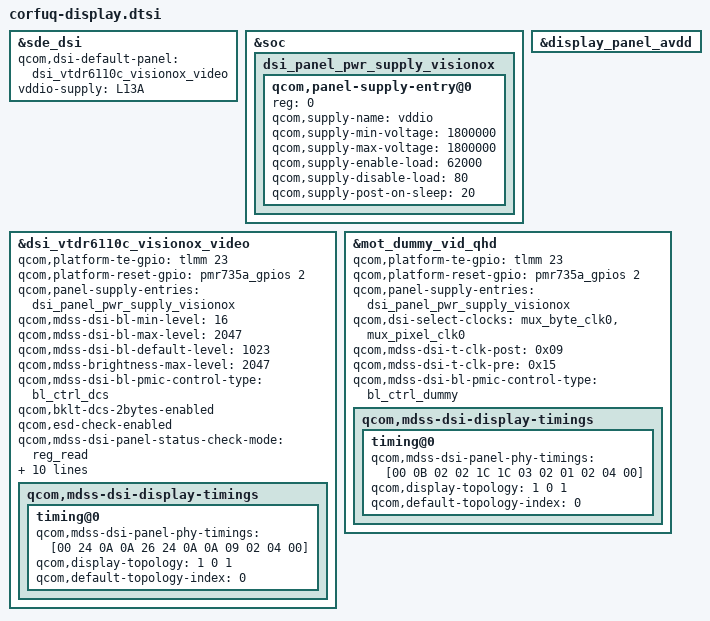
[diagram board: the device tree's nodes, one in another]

#include "dsi-panel-mot-visionox-vtdr6110c-fhd-video.dtsi"
#include "dsi-panel-mot-dummy-qhd-video.dtsi"


&sde_dsi {
	/delete-property/ qcom,dsi-default-panel;
	qcom,dsi-default-panel = <&dsi_vtdr6110c_visionox_video>;

	/delete-property/ avdd-supply;
	vddio-supply = <&L13A>;
};

&soc {
	dsi_panel_pwr_supply_visionox: dsi_panel_pwr_supply_visionox {
		#address-cells = <1>;
		#size-cells = <0>;

		qcom,panel-supply-entry@0 {
			reg = <0>;
			qcom,supply-name = "vddio";
			qcom,supply-min-voltage = <1800000>;
			qcom,supply-max-voltage = <1800000>;
			qcom,supply-enable-load = <62000>;
			qcom,supply-disable-load = <80>;
			qcom,supply-post-on-sleep = <20>;
		};
	};
};

&display_panel_avdd {
	/delete-property/ gpio;
	/delete-property/ pinctrl-0;
};

&dsi_vtdr6110c_visionox_video {
	qcom,platform-te-gpio = <&tlmm 23 0>;
	qcom,platform-reset-gpio = <&pmr735a_gpios 2 0>;

	qcom,panel-supply-entries = <&dsi_panel_pwr_supply_visionox>;

	qcom,mdss-dsi-bl-min-level = <16>;
	qcom,mdss-dsi-bl-max-level = <2047>;
	qcom,mdss-dsi-bl-default-level = <1023>;
	qcom,mdss-brightness-max-level = <2047>;
	qcom,mdss-dsi-bl-pmic-control-type = "bl_ctrl_dcs";
	qcom,bklt-dcs-2bytes-enabled;

	qcom,esd-check-enabled;
	qcom,mdss-dsi-panel-status-check-mode = "reg_read";
	qcom,mdss-dsi-panel-status-command = [06 01 00 01 00 00 01 0a];
	qcom,mdss-dsi-panel-status-command-state = "dsi_hs_mode";
	qcom,mdss-dsi-panel-status-value = <0x9c>;
	qcom,mdss-dsi-panel-status-read-length = <1>;

	qcom,dsi-select-clocks = "mux_byte_clk0", "mux_pixel_clk0";
	qcom,mdss-dsi-t-clk-post = <0x0F>;
	qcom,mdss-dsi-t-clk-pre = <0x3B>;
	qcom,mdss-dsi-display-timings {
		timing@0 {
			qcom,mdss-dsi-panel-phy-timings = [00 24 0A 0A 26 24 0A
				0A 09 02 04 00];
			qcom,display-topology = <1 0 1>;
			qcom,default-topology-index = <0>;
		};
	};
};

&mot_dummy_vid_qhd {
	qcom,platform-te-gpio = <&tlmm 23 0>;
	qcom,platform-reset-gpio = <&pmr735a_gpios 2 0>;

	qcom,panel-supply-entries = <&dsi_panel_pwr_supply_visionox>;

	qcom,dsi-select-clocks = "mux_byte_clk0", "mux_pixel_clk0";
	qcom,mdss-dsi-t-clk-post = <0x09>;
	qcom,mdss-dsi-t-clk-pre = <0x15>;
	qcom,mdss-dsi-bl-pmic-control-type = "bl_ctrl_dummy";
	qcom,mdss-dsi-display-timings {
		timing@0 {
			qcom,mdss-dsi-panel-phy-timings = [00 0B 02 02 1C 1C 03
							02 01 02 04 00];
			qcom,display-topology = <1 0 1>;
			qcom,default-topology-index = <0>;
		};
	};
};
